VERSION ""

NS_ :

BS_:

BU_: Acquisinator

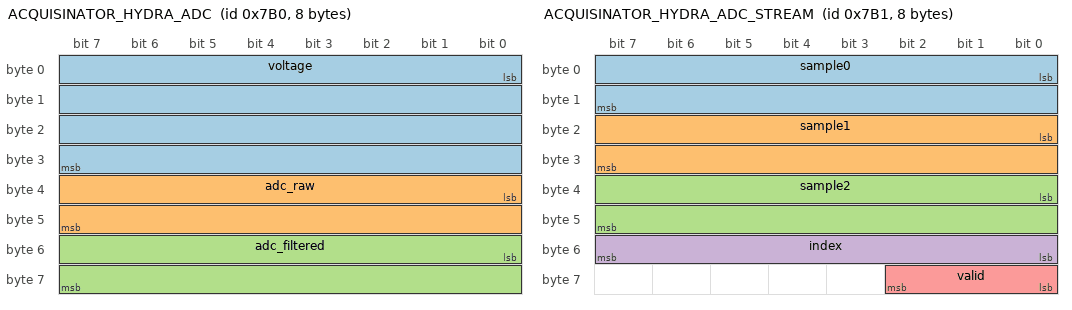
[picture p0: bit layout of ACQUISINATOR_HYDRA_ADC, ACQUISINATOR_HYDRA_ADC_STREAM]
BO_ 1968 ACQUISINATOR_HYDRA_ADC: 8 Acquisinator
 SG_ voltage : 0|32@1- (1,0) [0|3290] "mV" Vector__XXX
 SG_ adc_raw : 32|16@1+ (1,0) [0|65535] "code" Vector__XXX
 SG_ adc_filtered : 48|16@1+ (1,0) [0|65535] "code" Vector__XXX

BO_ 1969 ACQUISINATOR_HYDRA_ADC_STREAM: 8 Acquisinator
 SG_ sample0 : 0|16@1+ (1,0) [0|65535] "code" Vector__XXX
 SG_ sample1 : 16|16@1+ (1,0) [0|65535] "code" Vector__XXX
 SG_ sample2 : 32|16@1+ (1,0) [0|65535] "code" Vector__XXX
 SG_ index : 48|8@1+ (1,0) [0|255] "" Vector__XXX
 SG_ valid : 56|3@1+ (1,0) [0|7] "" Vector__XXX

CM_ SG_ 1968 voltage "Tensione sul canale dell'estensimetro (uscita amplificatore), da adc_filtered: 3290 mV * media / 65536";
CM_ SG_ 1968 adc_raw "Ultimo campione dell'LTC1865 (canale SE_CH2), non filtrato; campionamento a 1.5 kHz da timer, frame a ACQUISINATORE_ADC_SEND_RATE";
CM_ SG_ 1968 adc_filtered "Campioni a 1.5 kHz filtrati dal firmware (ACQUISINATORE_ADC_FILTER: media su 20 ms, oppure notch 50/100/150 Hz + passa basso a SEND_RATE/4), arrotondati; voltage ha il valore non arrotondato";
CM_ BO_ 1969 "Solo firmware dell'env raw (-DACQUISINATORE_RAW_STREAM): tutti i campioni grezzi dell'LTC1865 (SE_CH2) a 8 kHz, tre per frame in ordine di tempo";
CM_ SG_ 1969 index "Indice del primo campione (contatore dei tick di TIM2 mod 256): un salto diverso da 3 = frame persi";
CM_ SG_ 1969 valid "Bit k = campione k valido; 0 = errore SPI (codice 0)";
SIG_VALTYPE_ 1968 voltage : 1;
